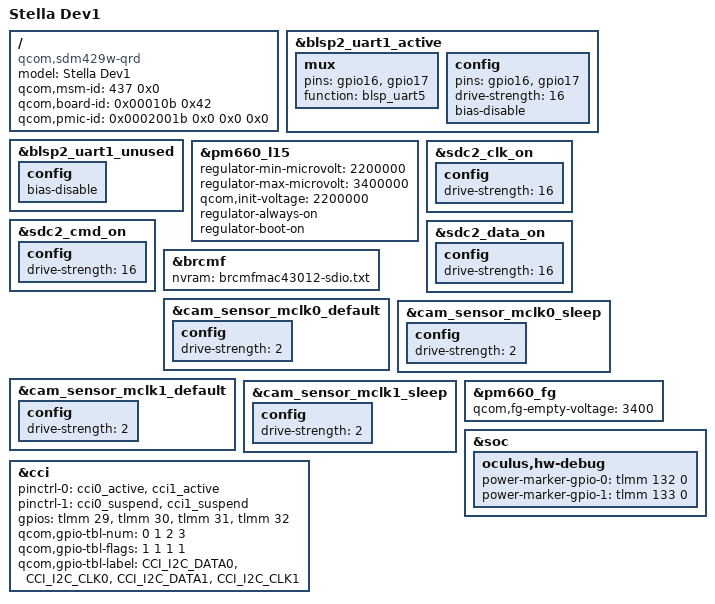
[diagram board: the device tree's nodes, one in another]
/*
 * Copyright (c) 2019, The Linux Foundation. All rights reserved.
 *
 * This program is free software; you can redistribute it and/or modify
 * it under the terms of the GNU General Public License version 2 and
 * only version 2 as published by the Free Software Foundation.
 *
 * This program is distributed in the hope that it will be useful,
 * but WITHOUT ANY WARRANTY; without even the implied warranty of
 * MERCHANTABILITY or FITNESS FOR A PARTICULAR PURPOSE.  See the
 * GNU General Public License for more details.
 */

/dts-v1/;
/plugin/;

#include "stella-common.dtsi"

/ {
	model = "Stella Dev1";
	compatible = "qcom,sdm429w-qrd", "qcom,sdm429w", "qcom,sda429w";
	qcom,msm-id = <437 0x0>;
	qcom,board-id = <0x00010b 0x42>;
	qcom,pmic-id = <0x0002001b 0x0 0x0 0x0>;
};

/* Use higher drive to get around of pull up from FTDI mux */
&blsp2_uart1_active {
	mux {
		pins = "gpio16", "gpio17";
		function = "blsp_uart5";
	};

	config {
		pins = "gpio16", "gpio17";
		drive-strength = <16>;
		bias-disable;
	};
};

&blsp2_uart1_unused {
	config {
		/delete-property/ bias-pull-down;
		bias-disable;
	};
};

&pm660_l15 {
	regulator-min-microvolt = <2200000>;
	regulator-max-microvolt = <3400000>;
	qcom,init-voltage = <2200000>;
	regulator-always-on;
	regulator-boot-on;
	status = "ok";
};

&sdc2_clk_on {
  config {
    drive-strength = <16>;
  };
};

&sdc2_cmd_on {
  config {
    drive-strength = <16>;
  };
};

&sdc2_data_on {
  config {
    drive-strength = <16>;
  };
};

&brcmf {
	nvram = "brcmfmac43012-sdio.txt";
};

&cam_sensor_mclk0_default {
	config {
		drive-strength = <2>;
	};
};

&cam_sensor_mclk0_sleep {
	config {
		drive-strength = <2>;
	};
};

&cam_sensor_mclk1_default {
	config {
		drive-strength = <2>;
	};
};

&cam_sensor_mclk1_sleep {
	config {
		drive-strength = <2>;
	};
};

&pm660_fg {
	qcom,fg-empty-voltage = <3400>;
};

&cci {
	pinctrl-0 = <&cci0_active &cci1_active>;
	pinctrl-1 = <&cci0_suspend &cci1_suspend>;
	gpios = <&tlmm 29 0>,
	<&tlmm 30 0>,
	<&tlmm 31 0>,
	<&tlmm 32 0>;
	qcom,gpio-tbl-num = <0 1 2 3>;
	qcom,gpio-tbl-flags = <1 1 1 1>;
	qcom,gpio-tbl-label = "CCI_I2C_DATA0",
				"CCI_I2C_CLK0",
				"CCI_I2C_DATA1",
				"CCI_I2C_CLK1";
};

&soc {
	oculus,hw-debug {
		power-marker-gpio-0 = <&tlmm 132 0>;
		power-marker-gpio-1 = <&tlmm 133 0>;
	};
};
